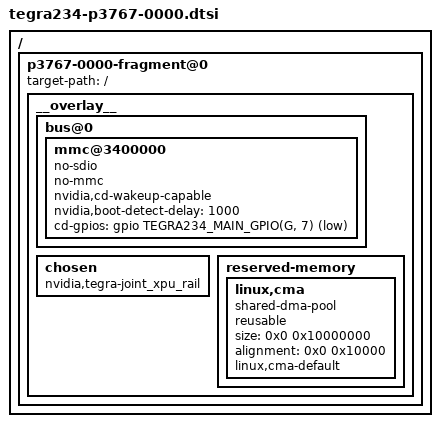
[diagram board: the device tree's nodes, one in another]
// SPDX-License-Identifier: GPL-2.0-only
// Copyright (c) 2023, NVIDIA CORPORATION & AFFILIATES.  All rights reserved.

#include <dt-bindings/gpio/tegra234-gpio.h>
#include <dt-bindings/interrupt-controller/arm-gic.h>
#include <dt-bindings/interrupt/tegra234-irq.h>

/ {
	p3767-0000-fragment@0 {
		target-path = "/";

		__overlay__ {
			bus@0 {
				mmc@3400000 {
					no-sdio;
					no-mmc;
					nvidia,cd-wakeup-capable;
					nvidia,boot-detect-delay = <1000>;
					cd-gpios = <&gpio TEGRA234_MAIN_GPIO(G, 7) GPIO_ACTIVE_LOW>;
				};
			};

			chosen {
				nvidia,tegra-joint_xpu_rail;
			};

			reserved-memory {
				linux,cma { /* Needed for nvgpu comptags */
					compatible = "shared-dma-pool";
					reusable;
					size = <0x0 0x10000000>; /* 256MB */
					alignment = <0x0 0x10000>;
					linux,cma-default;
					status = "okay";
				};
			};
		};
	};
};
